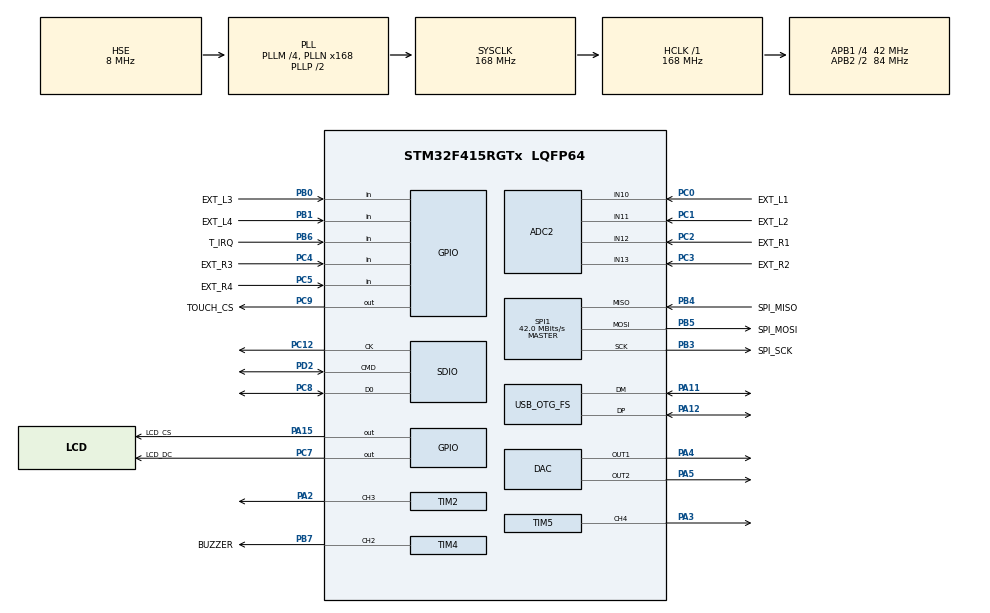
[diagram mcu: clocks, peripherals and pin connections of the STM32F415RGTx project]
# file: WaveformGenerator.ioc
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ADC2.Channel-0\#ChannelRegularConversion=ADC_CHANNEL_10
ADC2.NbrOfConversionFlag=1
ADC2.Rank-0\#ChannelRegularConversion=1
ADC2.SamplingTime-0\#ChannelRegularConversion=ADC_SAMPLETIME_3CYCLES
DAC.DAC_Trigger=DAC_TRIGGER_T6_TRGO
DAC.DAC_Trigger2=DAC_TRIGGER_T7_TRGO
DAC.WaveGeneration2=DISABLE
Dma.DAC1.4.Direction=DMA_MEMORY_TO_PERIPH
Dma.DAC1.4.FIFOMode=DMA_FIFOMODE_DISABLE
Dma.DAC1.4.Instance=DMA1_Stream5
Dma.DAC1.4.MemDataAlignment=DMA_MDATAALIGN_HALFWORD
Dma.DAC1.4.MemInc=DMA_MINC_ENABLE
Dma.DAC1.4.Mode=DMA_CIRCULAR
Dma.DAC1.4.PeriphDataAlignment=DMA_PDATAALIGN_HALFWORD
Dma.DAC1.4.PeriphInc=DMA_PINC_DISABLE
Dma.DAC1.4.Priority=DMA_PRIORITY_LOW
Dma.DAC2.5.Direction=DMA_MEMORY_TO_PERIPH
Dma.DAC2.5.FIFOMode=DMA_FIFOMODE_DISABLE
Dma.DAC2.5.Instance=DMA1_Stream6
Dma.DAC2.5.MemDataAlignment=DMA_MDATAALIGN_HALFWORD
Dma.DAC2.5.MemInc=DMA_MINC_ENABLE
Dma.DAC2.5.Mode=DMA_CIRCULAR
Dma.DAC2.5.PeriphDataAlignment=DMA_PDATAALIGN_HALFWORD
Dma.DAC2.5.PeriphInc=DMA_PINC_DISABLE
Dma.DAC2.5.Priority=DMA_PRIORITY_LOW
Dma.Request0=SPI1_RX
Dma.Request1=SPI1_TX
Dma.Request2=SDIO_RX
Dma.Request3=SDIO_TX
Dma.Request4=DAC1
Dma.Request5=DAC2
Dma.SDIO_RX.2.Direction=DMA_PERIPH_TO_MEMORY
Dma.SDIO_RX.2.FIFOMode=DMA_FIFOMODE_ENABLE
Dma.SDIO_RX.2.FIFOThreshold=DMA_FIFO_THRESHOLD_FULL
Dma.SDIO_RX.2.Instance=DMA2_Stream3
Dma.SDIO_RX.2.MemBurst=DMA_MBURST_INC4
Dma.SDIO_RX.2.MemDataAlignment=DMA_MDATAALIGN_WORD
Dma.SDIO_RX.2.MemInc=DMA_MINC_ENABLE
Dma.SDIO_RX.2.Mode=DMA_PFCTRL
Dma.SDIO_RX.2.PeriphBurst=DMA_PBURST_INC4
Dma.SDIO_RX.2.PeriphDataAlignment=DMA_PDATAALIGN_WORD
Dma.SDIO_RX.2.PeriphInc=DMA_PINC_DISABLE
Dma.SDIO_RX.2.Priority=DMA_PRIORITY_LOW
Dma.SDIO_TX.3.Direction=DMA_MEMORY_TO_PERIPH
Dma.SDIO_TX.3.FIFOMode=DMA_FIFOMODE_ENABLE
Dma.SDIO_TX.3.FIFOThreshold=DMA_FIFO_THRESHOLD_FULL
Dma.SDIO_TX.3.Instance=DMA2_Stream6
Dma.SDIO_TX.3.MemBurst=DMA_MBURST_INC4
Dma.SDIO_TX.3.MemDataAlignment=DMA_MDATAALIGN_WORD
Dma.SDIO_TX.3.MemInc=DMA_MINC_ENABLE
Dma.SDIO_TX.3.Mode=DMA_PFCTRL
Dma.SDIO_TX.3.PeriphBurst=DMA_PBURST_INC4
Dma.SDIO_TX.3.PeriphDataAlignment=DMA_PDATAALIGN_WORD
Dma.SDIO_TX.3.PeriphInc=DMA_PINC_DISABLE
Dma.SDIO_TX.3.Priority=DMA_PRIORITY_LOW
Dma.SPI1_RX.0.Direction=DMA_PERIPH_TO_MEMORY
Dma.SPI1_RX.0.FIFOMode=DMA_FIFOMODE_DISABLE
Dma.SPI1_RX.0.Instance=DMA2_Stream0
Dma.SPI1_RX.0.MemDataAlignment=DMA_MDATAALIGN_BYTE
Dma.SPI1_RX.0.MemInc=DMA_MINC_ENABLE
Dma.SPI1_RX.0.Mode=DMA_NORMAL
Dma.SPI1_RX.0.PeriphDataAlignment=DMA_PDATAALIGN_BYTE
Dma.SPI1_RX.0.PeriphInc=DMA_PINC_DISABLE
Dma.SPI1_RX.0.Priority=DMA_PRIORITY_MEDIUM
Dma.SPI1_TX.1.Direction=DMA_MEMORY_TO_PERIPH
Dma.SPI1_TX.1.FIFOMode=DMA_FIFOMODE_DISABLE
Dma.SPI1_TX.1.Instance=DMA2_Stream5
Dma.SPI1_TX.1.MemDataAlignment=DMA_MDATAALIGN_BYTE
Dma.SPI1_TX.1.MemInc=DMA_MINC_ENABLE
Dma.SPI1_TX.1.Mode=DMA_NORMAL
Dma.SPI1_TX.1.PeriphDataAlignment=DMA_PDATAALIGN_BYTE
Dma.SPI1_TX.1.PeriphInc=DMA_PINC_DISABLE
Dma.SPI1_TX.1.Priority=DMA_PRIORITY_HIGH
FREERTOS.INCLUDE_vTaskDelayUntil=1
FREERTOS.MEMORY_ALLOCATION=0
FREERTOS.Tasks01=defaultTask,3,128,StartDefaultTask,Default,NULL,Dynamic,NULL,NULL
FREERTOS.configCHECK_FOR_STACK_OVERFLOW=2
FREERTOS.configENABLE_BACKWARD_COMPATIBILITY=0
FREERTOS.configMINIMAL_STACK_SIZE=128
FREERTOS.configTIMER_QUEUE_LENGTH=8
FREERTOS.configTIMER_TASK_PRIORITY=6
FREERTOS.configTIMER_TASK_STACK_DEPTH=128
FREERTOS.configUSE_APPLICATION_TASK_TAG=1
FREERTOS.configUSE_MALLOC_FAILED_HOOK=1
FREERTOS.configUSE_NEWLIB_REENTRANT=1
FREERTOS.configUSE_RECURSIVE_MUTEXES=1
FREERTOS.configUSE_TASK_NOTIFICATIONS=1
FREERTOS.configUSE_TIMERS=1
Mcu.Family=STM32F4
Mcu.Name=STM32F415RGTx
Mcu.Package=LQFP64
NVIC.DMA1_Stream5_IRQn=true\:5\:0\:false\:false\:true\:true\:false\:true\:true
NVIC.DMA1_Stream6_IRQn=true\:5\:0\:false\:false\:true\:true\:false\:true\:true
NVIC.DMA2_Stream0_IRQn=true\:5\:0\:false\:false\:true\:true\:true\:true\:true
NVIC.DMA2_Stream3_IRQn=true\:5\:0\:false\:false\:true\:true\:true\:true\:true
NVIC.DMA2_Stream5_IRQn=true\:5\:0\:false\:false\:true\:true\:false\:true\:true
NVIC.DMA2_Stream6_IRQn=true\:5\:0\:false\:false\:true\:true\:false\:true\:true
NVIC.OTG_FS_IRQn=true\:5\:0\:false\:false\:true\:true\:false\:true\:true
NVIC.PriorityGroup=NVIC_PRIORITYGROUP_4
NVIC.SDIO_IRQn=true\:5\:0\:false\:false\:true\:true\:true\:true\:true
PA11.Mode=Device_Only
PA11.Signal=USB_OTG_FS_DM
PA12.Mode=Device_Only
PA12.Signal=USB_OTG_FS_DP
PA13.Mode=Serial_Wire
PA13.Signal=SYS_JTMS-SWDIO
PA14.Mode=Serial_Wire
PA14.Signal=SYS_JTCK-SWCLK
PA15.GPIO_Label=LCD_CS
PA15.GPIO_Speed=GPIO_SPEED_FREQ_VERY_HIGH
PA15.Signal=GPIO_Output
PA2.Signal=S_TIM2_CH3
PA3.Signal=S_TIM5_CH4
PA4.Signal=COMP_DAC1_group
PA5.Signal=COMP_DAC2_group
PB0.GPIO_Label=EXT_L3
PB0.Signal=GPIO_Input
PB1.GPIO_Label=EXT_L4
PB1.Signal=GPIO_Input
PB3.GPIO_Label=SPI_SCK
PB3.Mode=Full_Duplex_Master
PB3.Signal=SPI1_SCK
PB4.GPIO_Label=SPI_MISO
PB4.Mode=Full_Duplex_Master
PB4.Signal=SPI1_MISO
PB5.GPIO_Label=SPI_MOSI
PB5.Mode=Full_Duplex_Master
PB5.Signal=SPI1_MOSI
PB6.GPIO_Label=T_IRQ
PB6.Signal=GPIO_Input
PB7.GPIO_Label=BUZZER
PB7.Signal=S_TIM4_CH2
PC0.GPIO_Label=EXT_L1
PC0.Signal=ADCx_IN10
PC1.GPIO_Label=EXT_L2
PC1.Signal=ADCx_IN11
PC12.Mode=SD_1_bit
PC12.Signal=SDIO_CK
PC14-OSC32_IN.Mode=LSE-External-Oscillator
PC14-OSC32_IN.Signal=RCC_OSC32_IN
PC15-OSC32_OUT.Mode=LSE-External-Oscillator
PC15-OSC32_OUT.Signal=RCC_OSC32_OUT
PC2.GPIO_Label=EXT_R1
PC2.Signal=ADCx_IN12
PC3.GPIO_Label=EXT_R2
PC3.Signal=ADCx_IN13
PC4.GPIO_Label=EXT_R3
PC4.Signal=GPIO_Input
PC5.GPIO_Label=EXT_R4
PC5.Signal=GPIO_Input
PC7.GPIO_Label=LCD_DC
PC7.GPIO_Speed=GPIO_SPEED_FREQ_VERY_HIGH
PC7.Signal=GPIO_Output
PC8.GPIO_PuPd=GPIO_PULLUP
PC8.Mode=SD_1_bit
PC8.Signal=SDIO_D0
PC9.GPIO_Label=TOUCH_CS
PC9.GPIO_Speed=GPIO_SPEED_FREQ_VERY_HIGH
PC9.Signal=GPIO_Output
PD2.GPIO_PuPd=GPIO_PULLUP
PD2.Mode=SD_1_bit
PD2.Signal=SDIO_CMD
PH0-OSC_IN.Mode=HSE-External-Oscillator
PH0-OSC_IN.Signal=RCC_OSC_IN
PH1-OSC_OUT.Mode=HSE-External-Oscillator
PH1-OSC_OUT.Signal=RCC_OSC_OUT
ProjectManager.HeapSize=0x0000
ProjectManager.StackSize=0x0010
ProjectManager.TargetToolchain=STM32CubeIDE
RCC.48MHZClocksFreq_Value=48000000
RCC.AHBFreq_Value=168000000
RCC.APB1CLKDivider=RCC_HCLK_DIV4
RCC.APB1Freq_Value=42000000
RCC.APB1TimFreq_Value=84000000
RCC.APB2CLKDivider=RCC_HCLK_DIV2
RCC.APB2Freq_Value=84000000
RCC.APB2TimFreq_Value=168000000
RCC.CortexFreq_Value=168000000
RCC.HCLKFreq_Value=168000000
RCC.HSE_VALUE=8000000
RCC.HSI_VALUE=16000000
RCC.PLLM=4
RCC.PLLN=168
RCC.PLLQ=7
RCC.SYSCLKFreq_VALUE=168000000
RCC.SYSCLKSource=RCC_SYSCLKSOURCE_PLLCLK
RCC.VCOOutputFreq_Value=336000000
SH.ADCx_IN10.0=ADC2_IN10,IN10
SH.ADCx_IN11.0=ADC2_IN11,IN11
SH.ADCx_IN12.0=ADC2_IN12,IN12
SH.ADCx_IN13.0=ADC2_IN13,IN13
SH.COMP_DAC1_group.0=DAC_OUT1,DAC_OUT1
SH.COMP_DAC2_group.0=DAC_OUT2,DAC_OUT2
SH.S_TIM2_CH3.0=TIM2_CH3,PWM Generation3 CH3
SH.S_TIM4_CH2.0=TIM4_CH2,Output Compare2 CH2
SH.S_TIM5_CH4.0=TIM5_CH4,PWM Generation4 CH4
SPI1.BaudRatePrescaler=SPI_BAUDRATEPRESCALER_2
SPI1.CalculateBaudRate=42.0 MBits/s
SPI1.Direction=SPI_DIRECTION_2LINES
SPI1.Mode=SPI_MODE_MASTER
SPI1.VirtualType=VM_MASTER
TIM2.Channel-PWM\ Generation3\ CH3=TIM_CHANNEL_3
TIM4.Channel-Output\ Compare2\ CH2=TIM_CHANNEL_2
TIM4.OCMode_2=TIM_OCMODE_TOGGLE
TIM4.Period=50
TIM5.Channel-PWM\ Generation4\ CH4=TIM_CHANNEL_4
TIM6.Prescaler=0
TIM6.TIM_MasterOutputTrigger=TIM_TRGO_UPDATE
TIM7.Prescaler=0
TIM7.TIM_MasterOutputTrigger=TIM_TRGO_UPDATE
USB_DEVICE.CLASS_NAME_FS=CDC
USB_DEVICE.MANUFACTURER_STRING-CDC_FS=DevBoy
USB_DEVICE.VirtualMode-CDC_FS=Cdc
USB_DEVICE.VirtualModeFS=Cdc_FS
USB_OTG_FS.VirtualMode=Device_Only
VP_FATFS_VS_SDIO.Mode=SDIO
VP_FREERTOS_VS_CMSIS_V1.Mode=CMSIS_V1
VP_RTC_VS_RTC_Activate.Mode=RTC_Enabled
VP_TIM2_VS_ClockSourceINT.Mode=Internal
VP_TIM5_VS_ClockSourceINT.Mode=Internal
VP_TIM6_VS_ClockSourceINT.Mode=Enable_Timer
VP_TIM7_VS_ClockSourceINT.Mode=Enable_Timer
VP_USB_DEVICE_VS_USB_DEVICE_CDC_FS.Mode=CDC_FS
board=custom

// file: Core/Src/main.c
/* USER CODE BEGIN Header */
/**
  ******************************************************************************
  * @file           : main.c
  * @brief          : Main program body
  ******************************************************************************
  * @attention
  *
  * Copyright (c) 2023 STMicroelectronics.
  * All rights reserved.
  *
  * This software is licensed under terms that can be found in the LICENSE file
  * in the root directory of this software component.
  * If no LICENSE file comes with this software, it is provided AS-IS.
  *
  ******************************************************************************
  */
/* USER CODE END Header */
#include "main.h"
#include "cmsis_os.h"
#include "adc.h"
#include "dac.h"
#include "dma.h"
#include "fatfs.h"
#include "rtc.h"
#include "sdio.h"
#include "spi.h"
#include "tim.h"
#include "usb_device.h"
#include "gpio.h"

void SystemClock_Config(void);
void MX_FREERTOS_Init(void);
/* USER CODE BEGIN PFP */
extern void AppMain(void);
/* USER CODE END PFP */

int main(void)
{

  /* MCU Configuration--------------------------------------------------------*/

  /* Reset of all peripherals, Initializes the Flash interface and the Systick. */
  HAL_Init();

  /* Configure the system clock */
  SystemClock_Config();

  /* Initialize all configured peripherals */
  MX_GPIO_Init();
  MX_DMA_Init();
  MX_SPI1_Init();
  MX_TIM4_Init();
  MX_ADC2_Init();
  MX_SDIO_SD_Init();
  MX_RTC_Init();
  MX_FATFS_Init();
  MX_DAC_Init();
  MX_TIM6_Init();
  MX_TIM7_Init();
  MX_TIM5_Init();
  MX_TIM2_Init();
  /* USER CODE BEGIN 2 */
  AppMain();
  /* USER CODE END 2 */

  /* Call init function for freertos objects (in cmsis_os2.c) */
  MX_FREERTOS_Init();

  /* Start scheduler */
  osKernelStart();

  /* We should never get here as control is now taken by the scheduler */

  /* Infinite loop */
  while (1)
  {

  }
}

void SystemClock_Config(void)
{
  RCC_OscInitTypeDef RCC_OscInitStruct = {0};
  RCC_ClkInitTypeDef RCC_ClkInitStruct = {0};

  /** Configure the main internal regulator output voltage
  */
  __HAL_RCC_PWR_CLK_ENABLE();
  __HAL_PWR_VOLTAGESCALING_CONFIG(PWR_REGULATOR_VOLTAGE_SCALE1);

  /** Initializes the RCC Oscillators according to the specified parameters
  * in the RCC_OscInitTypeDef structure.
  */
  RCC_OscInitStruct.OscillatorType = RCC_OSCILLATORTYPE_LSI|RCC_OSCILLATORTYPE_HSE;
  RCC_OscInitStruct.HSEState = RCC_HSE_ON;
  RCC_OscInitStruct.LSIState = RCC_LSI_ON;
  RCC_OscInitStruct.PLL.PLLState = RCC_PLL_ON;
  RCC_OscInitStruct.PLL.PLLSource = RCC_PLLSOURCE_HSE;
  RCC_OscInitStruct.PLL.PLLM = 4;
  RCC_OscInitStruct.PLL.PLLN = 168;
  RCC_OscInitStruct.PLL.PLLP = RCC_PLLP_DIV2;
  RCC_OscInitStruct.PLL.PLLQ = 7;
  if (HAL_RCC_OscConfig(&RCC_OscInitStruct) != HAL_OK)
  {
    Error_Handler();
  }

  /** Initializes the CPU, AHB and APB buses clocks
  */
  RCC_ClkInitStruct.ClockType = RCC_CLOCKTYPE_HCLK|RCC_CLOCKTYPE_SYSCLK
                              |RCC_CLOCKTYPE_PCLK1|RCC_CLOCKTYPE_PCLK2;
  RCC_ClkInitStruct.SYSCLKSource = RCC_SYSCLKSOURCE_PLLCLK;
  RCC_ClkInitStruct.AHBCLKDivider = RCC_SYSCLK_DIV1;
  RCC_ClkInitStruct.APB1CLKDivider = RCC_HCLK_DIV4;
  RCC_ClkInitStruct.APB2CLKDivider = RCC_HCLK_DIV2;

  if (HAL_RCC_ClockConfig(&RCC_ClkInitStruct, FLASH_LATENCY_5) != HAL_OK)
  {
    Error_Handler();
  }
}

void Error_Handler(void)
{
  __disable_irq();
  while (1)
  {
  }
}
